# CTRL_MMR0_CFG0 register map
Vendor: Texas Instruments
Registers are 32-bit, read-write, reset 0x0 unless marked. A register's access mark holds for its fields unless they carry their own. Offsets are as the file gives them; [hi:lo] are bit positions; {n}, {i} and the like mark numbered series.

## CTRL_MMR0_CFG0 (part 2 of 2)
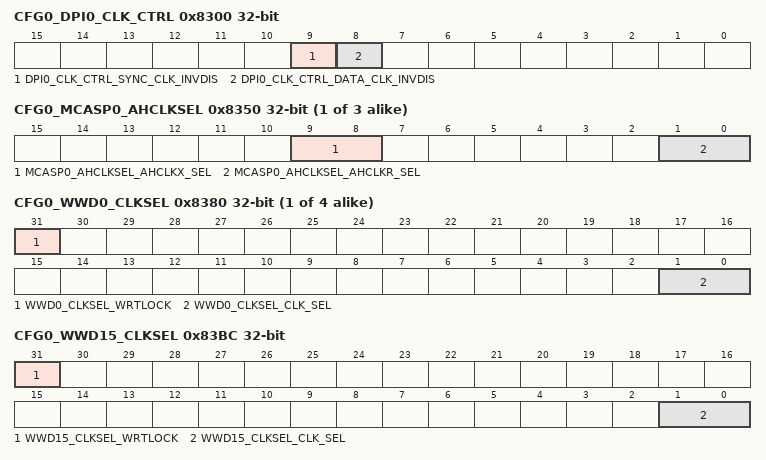
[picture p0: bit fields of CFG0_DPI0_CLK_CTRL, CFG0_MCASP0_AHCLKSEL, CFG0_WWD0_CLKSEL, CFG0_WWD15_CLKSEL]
0x8300 CFG0_DPI0_CLK_CTRL
  [9] DPI0_CLK_CTRL_SYNC_CLK_INVDIS — Clock edge select for DPI0 sync outputs 0 - HSYNC and VSYNC are driven on the falling edge of clk 1 - HSYNC and VSYNC are driven on the rising edge of clk Note that this value should align with the programmed value of the DSS POL_FREQ.RF bitfield.8
  [8] DPI0_CLK_CTRL_DATA_CLK_INVDIS — Clock edge select for DPI0 data outputs 0 - DATA and DE are driven on the falling edge of clk 1 - DATA and DE are driven on the rising edge of clk Note that this value should align with the programmed valueof the DSS POL_FREQ.IPC bitfield.0
0x8320 CFG0_DSS_DISPC0_CLKSEL1
  [0] DSS_DISPC0_CLKSEL1_DPI1_PCLK — DPI Lane 1 pixel Clock Source Field values (others are reserved): 1'b0 - MAIN_PLL17_HSDIV0_CLKOUT 1'b1 - VOUT0_EXTPCLKIN
{0x8330+4i} CFG0_MCASP{i}_CLKSEL (i=0..2)
  [0] MCASP{i}_CLKSEL_AUXCLK_SEL — Selects the AUXCLK input source for McASP0 Field values (others are reserved): 1'b0 - MAIN_PLL2_HSDIV8_CLKOUT 1'b1 - MAIN_PLL1_HSDIV6_CLKOUT
{0x8350+4i} CFG0_MCASP{i}_AHCLKSEL (i=0..2)
  [9:8] MCASP{i}_AHCLKSEL_AHCLKX_SEL — Selects the AHCLKX input source for McASP{i} Field values (others are reserved): 2'b00 - EXT_REFCLK1 (pin) 2'b01 - HFOSC0_CLKOUT 2'b10 - AUDIO_EXT_REFCLK0_IN 2'b11 - AUDIO_EXT_REFCLK1_IN
  [1:0] MCASP{i}_AHCLKSEL_AHCLKR_SEL — Selects the AHCLKR input source for McASP{i} Field values (others are reserved): 2'b00 - EXT_REFCLK1 (pin) 2'b01 - HFOSC0_CLKOUT 2'b10 - AUDIO_EXT_REFCLK0_IN 2'b11 - AUDIO_EXT_REFCLK1_IN
{0x8380+4i} CFG0_WWD{i}_CLKSEL (i=0..3)
  [31] WWD{i}_CLKSEL_WRTLOCK — When set, locks WWD{i}_CLKSEL from further writes until the next module reset.
  [1:0] WWD{i}_CLKSEL_CLK_SEL — Windowed watchdog timer functional clock input select mux control Field values (others are reserved): 2'b00 - HFOSC0_CLKOUT 2'b01 - DEVICE_CLKOUT_32K 2'b10 - CLK_12M_RC 2'b11 - CLK_32K
0x83BC CFG0_WWD15_CLKSEL
  [31] WWD15_CLKSEL_WRTLOCK — When set, locks WWD15_CLKSEL from further writes until the next module reset.
  [1:0] WWD15_CLKSEL_CLK_SEL — Windowed watchdog timer functional clock input select mux control Field values (others are reserved): 2'b00 - HFOSC0_CLKOUT 2'b01 - DEVICE_CLKOUT_32K 2'b10 - CLK_12M_RC 2'b11 - CLK_32K
0x8480 CFG0_MCAN0_CLKSEL
  [1:0] MCAN0_CLKSEL_CLK_SEL — MAIN MCAN_CLK selection 2'b00 - MAIN_PLL0_HSDIV3_CLKOUT 2'b01 - MCU_EXT_REFCLK0 (pin) 2'b10 - EXT_REFCLK0 (pin) 2'b11 - HFOSC0_CLKOUT Field values (others are reserved): 2'b00 - MAIN_PLL0_HSDIV4_CLKOUT 2'b01 - MCU_EXT_REFCLK0 2'b10 - EXT_REFCLK1 (pin) 2'b11 - HFOSC0_CLKOUT
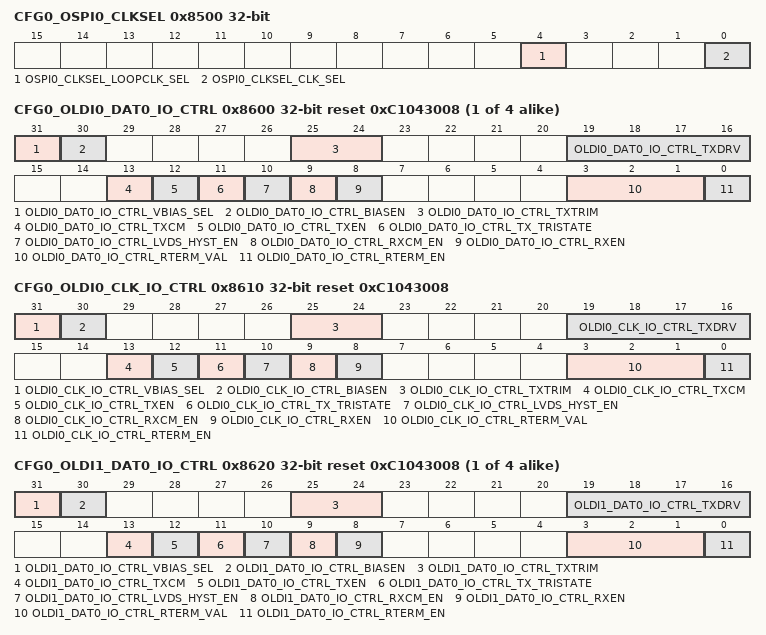
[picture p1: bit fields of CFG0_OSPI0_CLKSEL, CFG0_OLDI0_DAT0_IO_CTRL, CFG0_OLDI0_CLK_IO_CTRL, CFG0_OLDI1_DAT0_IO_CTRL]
0x8500 CFG0_OSPI0_CLKSEL
  [4] OSPI0_CLKSEL_LOOPCLK_SEL — OBSPI0 Loopback clock source Field values (others are reserved): 1'b0 - Board Level Loopback 1'b1 - Internal Loopback
  [0] OSPI0_CLKSEL_CLK_SEL — OSPI0 reference clock selection Field values (others are reserved): 1'b0 - MAIN_PLL0_HSDIV1_CLKOUT 1'b1 - MAIN_PLL1_HSDIV5_CLKOUT
{0x8600+4i} CFG0_OLDI0_DAT{i}_IO_CTRL reset 0xC1043008 (i=0..3)
  [31] OLDI0_DAT{i}_IO_CTRL_VBIAS_SEL — Selects LVDS IO Bias Voltage
  [30] OLDI0_DAT{i}_IO_CTRL_BIASEN — Controls LVDS IO BIAS_EN if OLDI is activated
  [25:24] OLDI0_DAT{i}_IO_CTRL_TXTRIM — Controls LVDS Transmitter TXTRIM
  [19:16] OLDI0_DAT{i}_IO_CTRL_TXDRV — Controls LVDS Transmitter TXDRV
  [13] OLDI0_DAT{i}_IO_CTRL_TXCM — Controls LVDS Transmitter TX_CM
  [12] OLDI0_DAT{i}_IO_CTRL_TXEN — Controls LVDS Transmitter TXEN if BIAS_EN is active
  [11] OLDI0_DAT{i}_IO_CTRL_TX_TRISTATE — Controls LVDS Transmitter TX_TRISTATE input if BIAS_EN is active
  [10] OLDI0_DAT{i}_IO_CTRL_LVDS_HYST_EN — Controls LVDS Receiver Hysteresis
  [9] OLDI0_DAT{i}_IO_CTRL_RXCM_EN — Controls LVDS Receiver RXCM_EN
  [8] OLDI0_DAT{i}_IO_CTRL_RXEN — Controls LVDS Receiver RXEN when BIAS_EN is active
  [3:1] OLDI0_DAT{i}_IO_CTRL_RTERM_VAL — Controls LVDS Receiver RTERM_VAL
  [0] OLDI0_DAT{i}_IO_CTRL_RTERM_EN — Controls LVDS Receiver RTERM_EN
0x8610 CFG0_OLDI0_CLK_IO_CTRL reset 0xC1043008
  [31] OLDI0_CLK_IO_CTRL_VBIAS_SEL — Selects LVDS IO Bias Voltage
  [30] OLDI0_CLK_IO_CTRL_BIASEN — Controls LVDS IO BIAS_EN if OLDI is activated
  [25:24] OLDI0_CLK_IO_CTRL_TXTRIM — Controls LVDS Transmitter TXTRIM
  [19:16] OLDI0_CLK_IO_CTRL_TXDRV — Controls LVDS Transmitter TXDRV
  [13] OLDI0_CLK_IO_CTRL_TXCM — Controls LVDS Transmitter TX_CM
  [12] OLDI0_CLK_IO_CTRL_TXEN — Controls LVDS Transmitter TXEN if BIAS_EN is active
  [11] OLDI0_CLK_IO_CTRL_TX_TRISTATE — Controls LVDS Transmitter TX_TRISTATE input if BIAS_EN is active
  [10] OLDI0_CLK_IO_CTRL_LVDS_HYST_EN — Controls LVDS Receiver Hysteresis
  [9] OLDI0_CLK_IO_CTRL_RXCM_EN — Controls LVDS Receiver RXCM_EN
  [8] OLDI0_CLK_IO_CTRL_RXEN — Controls LVDS Receiver RXEN when BIAS_EN is active
  [3:1] OLDI0_CLK_IO_CTRL_RTERM_VAL — Controls LVDS Receiver RTERM_VAL
  [0] OLDI0_CLK_IO_CTRL_RTERM_EN — Controls LVDS Receiver RTERM_EN
{0x8620+4i} CFG0_OLDI1_DAT{i}_IO_CTRL reset 0xC1043008 (i=0..3)
  [31] OLDI1_DAT{i}_IO_CTRL_VBIAS_SEL — Selects LVDS IO Bias Voltage
  [30] OLDI1_DAT{i}_IO_CTRL_BIASEN — Controls LVDS IO BIAS_EN if OLDI is activated
  [25:24] OLDI1_DAT{i}_IO_CTRL_TXTRIM — Controls LVDS Transmitter TXTRIM
  [19:16] OLDI1_DAT{i}_IO_CTRL_TXDRV — Controls LVDS Transmitter TXDRV
  [13] OLDI1_DAT{i}_IO_CTRL_TXCM — Controls LVDS Transmitter TX_CM
  [12] OLDI1_DAT{i}_IO_CTRL_TXEN — Controls LVDS Transmitter TXEN if BIAS_EN is active
  [11] OLDI1_DAT{i}_IO_CTRL_TX_TRISTATE — Controls LVDS Transmitter TX_TRISTATE input if BIAS_EN is active
  [10] OLDI1_DAT{i}_IO_CTRL_LVDS_HYST_EN — Controls LVDS Receiver Hysteresis
  [9] OLDI1_DAT{i}_IO_CTRL_RXCM_EN — Controls LVDS Receiver RXCM_EN
  [8] OLDI1_DAT{i}_IO_CTRL_RXEN — Controls LVDS Receiver RXEN when BIAS_EN is active
  [3:1] OLDI1_DAT{i}_IO_CTRL_RTERM_VAL — Controls LVDS Receiver RTERM_VAL
  [0] OLDI1_DAT{i}_IO_CTRL_RTERM_EN — Controls LVDS Receiver RTERM_EN
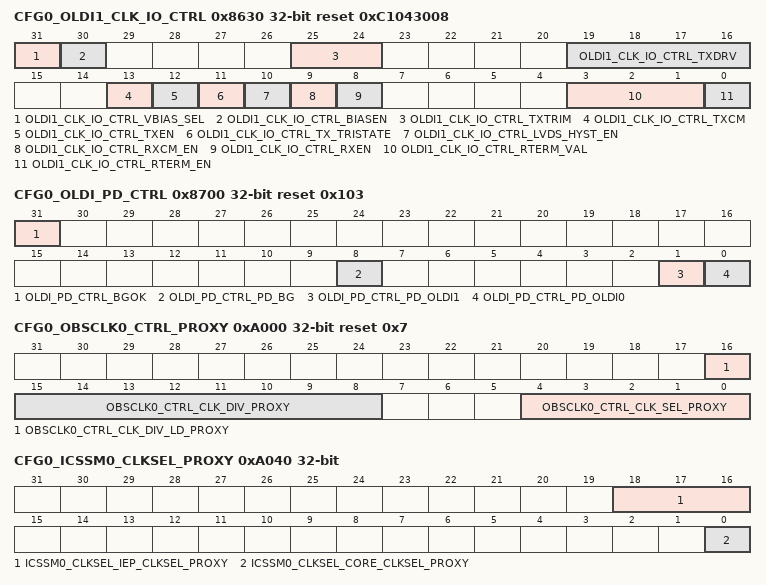
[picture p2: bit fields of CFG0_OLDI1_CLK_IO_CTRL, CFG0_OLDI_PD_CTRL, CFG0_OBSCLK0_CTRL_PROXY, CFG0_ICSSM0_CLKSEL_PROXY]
0x8630 CFG0_OLDI1_CLK_IO_CTRL reset 0xC1043008
  [31] OLDI1_CLK_IO_CTRL_VBIAS_SEL — Selects LVDS IO Bias Voltage
  [30] OLDI1_CLK_IO_CTRL_BIASEN — Controls LVDS IO BIAS_EN if OLDI is activated
  [25:24] OLDI1_CLK_IO_CTRL_TXTRIM — Controls LVDS Transmitter TXTRIM
  [19:16] OLDI1_CLK_IO_CTRL_TXDRV — Controls LVDS Transmitter TXDRV
  [13] OLDI1_CLK_IO_CTRL_TXCM — Controls LVDS Transmitter TX_CM
  [12] OLDI1_CLK_IO_CTRL_TXEN — Controls LVDS Transmitter TXEN if BIAS_EN is active
  [11] OLDI1_CLK_IO_CTRL_TX_TRISTATE — Controls LVDS Transmitter TX_TRISTATE input if BIAS_EN is active
  [10] OLDI1_CLK_IO_CTRL_LVDS_HYST_EN — Controls LVDS Receiver Hysteresis
  [9] OLDI1_CLK_IO_CTRL_RXCM_EN — Controls LVDS Receiver RXCM_EN
  [8] OLDI1_CLK_IO_CTRL_RXEN — Controls LVDS Receiver RXEN when BIAS_EN is active
  [3:1] OLDI1_CLK_IO_CTRL_RTERM_VAL — Controls LVDS Receiver RTERM_VAL
  [0] OLDI1_CLK_IO_CTRL_RTERM_EN — Controls LVDS Receiver RTERM_EN
0x8700 CFG0_OLDI_PD_CTRL access per field reset 0x103
  [31] OLDI_PD_CTRL_BGOK ro — Status of the Bandgap: 1 = Bandgap is On
  [8] OLDI_PD_CTRL_PD_BG rw — When Set, forces the LVDS Bandgap into Power Down
  [1] OLDI_PD_CTRL_PD_OLDI1 rw — When Set, overrides the biase_en of all OLDI1 LVDS IO to force power down
  [0] OLDI_PD_CTRL_PD_OLDI0 rw — When Set, overrides the biase_en of all OLDI0 LVDS IO to force power down
0x8704 CFG0_OLDI_LB_CTRL
  [0] OLDI_LB_CTRL_OLDI_SEL — When: 0 - OLDI0 loopback data is routed to DSS 1 - OLDI1 loopback data is routed to DSS
{0x9100+4i} CFG0_CLAIMREG_P2_R{i}_READONLY ro (i=0..14)
  [31:0] CLAIMREG_P2_R{i}_READONLY — Claim bits for Partition 2
0xA000 CFG0_OBSCLK0_CTRL_PROXY reset 0x7
  [16] OBSCLK0_CTRL_CLK_DIV_LD_PROXY — Load the output divider value Writing 1 to this bit will generate a load pulse to load the OBSCLK0 divider value. This bit can be cleared but must not be set in the same write cycle in which the clk_div value is changed.
  [15:8] OBSCLK0_CTRL_CLK_DIV_PROXY — OBSCLK0 output divider Divides the selected clock by clkdiv+1 for output to the OBSCLK0 pins. Supports divide by 1 to 256 (default to 1). To load the new divider value the clk_div_ld bit must be cleared and then set to 1.
  [4:0] OBSCLK0_CTRL_CLK_SEL_PROXY — OBSCLK0 clock source selection. Selects the source of the clock to be divided by the OBSCLK0 divider and output on the OBSCLK0 pin. Field values (others are reserved): 5'b00000 - MAIN_PLL0_HSDIV0_CLKOUT 5'b00001 - MAIN_PLL1_HSDIV0_CLKOUT 5'b00010 - MAIN_PLL2_HSDIV0_CLKOUT 5'b00011 - MAIN_PLL8_HSDIV0_CLKOUT 5'b00100 - MAIN_PLL12_HSDIV0_CLKOUT 5'b00101 - CLK_12M_RC 5'b00110 - HFOSC0_CLKOUT_32K 5'b00111 - PLLCTRL_OBSCLK 5'b01000 - HFOSC0_CLKOUT 5'b01001 - CLK_32K 5'b01010 - cpsw2g_cpts_genf0 5'b01011 - cpsw2g_cpts_genf1 5'b01100 - MCU_PLL0_HSDIV0_CLKOUT 5'b01101 - MAIN_PLL15_HSDIV0_CLKOUT 5'b01110 - MAIN_PLL16_HSDIV0_CLKOUT 5'b01111 - MAIN_PLL17_HSDIV0_CLKOUT 5'b10000 - MAIN_SYSCLK0 5'b10001 - DEVICE_CLKOUT_32K
0xA010 CFG0_CLKOUT_CTRL_PROXY
  [0] CLKOUT_CTRL_CLK_SEL_PROXY — Selects CLKOUT clock source Field values (others are reserved): 1'b0 - MAIN_PLL2_HSDIV1_CLKOUT / 5 1'b1 - MAIN_PLL2_HSDIV1_CLKOUT / 10
0xA040 CFG0_ICSSM0_CLKSEL_PROXY
  [18:16] ICSSM0_CLKSEL_IEP_CLKSEL_PROXY — Selects the ICSSM0 IEP clock source Field values (others are reserved): 3'b000 - MAIN_PLL2_HSDIV5_CLKOUT 3'b001 - MAIN_PLL0_HSDIV6_CLKOUT 3'b010 - CPGEMAC_CPTS_RFT_CLK 3'b011 - reserved 3'b100 - MCU_EXT_REFCLK0 3'b101 - EXT_REFCLK1 3'b110 - MCU_SYSCLK0 3'b111 - MAIN_SYSCLK0
  [0] ICSSM0_CLKSEL_CORE_CLKSEL_PROXY — Selects the ICSSM0 functional clock source Field values (others are reserved): 1'b0 - MAIN_PLL2_HSDIV0_CLKOUT 1'b1 - MAIN_PLL0_HSDIV9_CLKOUT
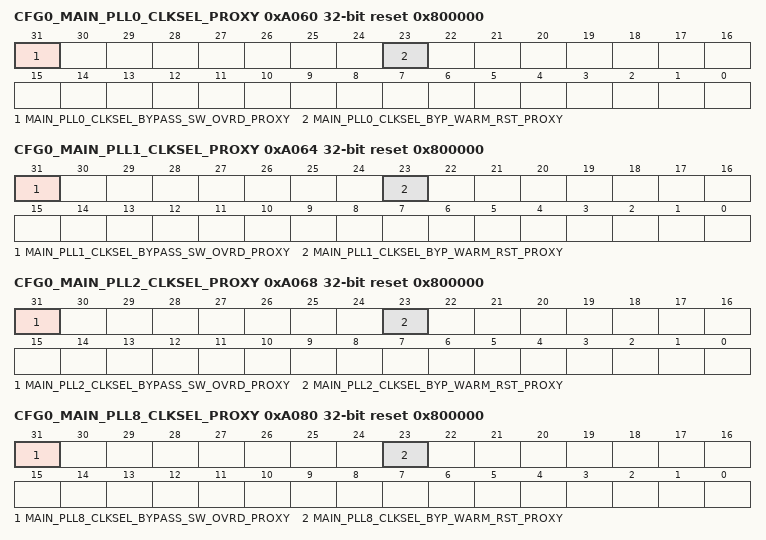
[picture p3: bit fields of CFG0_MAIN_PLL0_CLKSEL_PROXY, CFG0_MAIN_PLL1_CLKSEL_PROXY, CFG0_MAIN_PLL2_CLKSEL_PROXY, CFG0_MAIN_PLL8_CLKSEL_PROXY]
0xA060 CFG0_MAIN_PLL0_CLKSEL_PROXY reset 0x800000
  [31] MAIN_PLL0_CLKSEL_BYPASS_SW_OVRD_PROXY — PLL Bypass warm reset software override When set, activates software control of exit from bypass mode on a main_reset_z for MAIN PLL0. This bit must not be set until after the corresponding byp_warm_rst bit has been cleared or the PLL will immediately enter bypass mode.
  [23] MAIN_PLL0_CLKSEL_BYP_WARM_RST_PROXY — PLL bypass mode after warm reset. This bit is only valid when bypass_sw_ovrd is set to 1'b1 to activate bypass software override. This bit is set (1'b0) when a MAIN warm reset occurs to keep MAIN PLL0 from being bypassed, supporting reset isolation of the CPSW. 1'b0 = Exit bypass mode (based on MAIN PLL0_CTRL_bypass_en bit value) 1'b1 = Maintain bypass mode.
0xA064 CFG0_MAIN_PLL1_CLKSEL_PROXY reset 0x800000
  [31] MAIN_PLL1_CLKSEL_BYPASS_SW_OVRD_PROXY — PLL Bypass warm reset software override This bit has no effect on PLL operation as MAIN PLL1 is reset isolated and exit from bypass mode (in the case of a Thermal reset) is always hardware controlled.
  [23] MAIN_PLL1_CLKSEL_BYP_WARM_RST_PROXY — PLL bypass mode after warm reset. This bit is cleared to 1'b0 when a MAIN warm reset occurs which will cause MAIN PLL1 to exit bypass mode after reset exit. Setting this bit will have no effect on PLL behaviot. Because MAIN PLL1 is warm reset insensitive, bypass mode will only be entered (and exited) in the case of a Thermal reset event.
0xA068 CFG0_MAIN_PLL2_CLKSEL_PROXY reset 0x800000
  [31] MAIN_PLL2_CLKSEL_BYPASS_SW_OVRD_PROXY — PLL Bypass warm reset software override This bit has no effect on PLL operation as MAIN PLL2 is reset isolated and exit from bypass mode (in the case of a Thermal reset) is always hardware controlled.
  [23] MAIN_PLL2_CLKSEL_BYP_WARM_RST_PROXY — PLL bypass mode after warm reset. This bit is cleared to 1'b0 when a MAIN warm reset occurs which will cause MAIN PLL2 to exit bypass mode after reset exit. Setting this bit will have no effect on PLL behaviot. Because MAIN PLL2 is warm reset insensitive, bypass mode will only be entered (and exited) in the case of a Thermal reset event.
0xA080 CFG0_MAIN_PLL8_CLKSEL_PROXY reset 0x800000
  [31] MAIN_PLL8_CLKSEL_BYPASS_SW_OVRD_PROXY — PLL Bypass warm reset software override When set, activates software control of exit from bypass mode on a main_reset_z for MAIN PLL8. This bit must not be set until after the corresponding byp_warm_rst bit has been cleared or the PLL will immediately enter bypass mode.
  [23] MAIN_PLL8_CLKSEL_BYP_WARM_RST_PROXY — PLL bypass mode after warm reset. This bit is only valid when bypass_sw_ovrd is set to 1'b1 to activate bypass software override. This bit is set (1'b1) when a MAIN warm reset occurs and will keep MAIN PLL8 in bypass mode after reset exit until cleared by software. 1'b0 = Exit bypass mode (based on MAIN PLL8_CTRL_bypass_en bit value) 1'b1 = Maintain bypass mode.
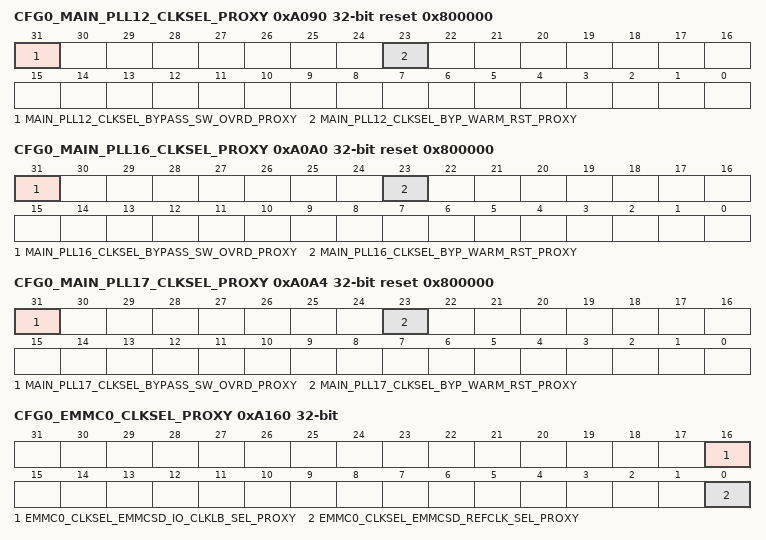
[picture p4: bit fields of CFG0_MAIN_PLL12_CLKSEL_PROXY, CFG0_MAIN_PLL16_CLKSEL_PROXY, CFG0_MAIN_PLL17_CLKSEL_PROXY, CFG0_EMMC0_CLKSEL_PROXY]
0xA090 CFG0_MAIN_PLL12_CLKSEL_PROXY reset 0x800000
  [31] MAIN_PLL12_CLKSEL_BYPASS_SW_OVRD_PROXY — PLL Bypass warm reset software override When set, activates software control of exit from bypass mode on a main_reset_z for MAIN PLL12. This bit must not be set until after the corresponding byp_warm_rst bit has been cleared or the PLL will immediately enter bypass mode.
  [23] MAIN_PLL12_CLKSEL_BYP_WARM_RST_PROXY — PLL bypass mode after warm reset. This bit is only valid when bypass_sw_ovrd is set to 1'b1 to activate bypass software override. This bit is set (1'b1) when a MAIN warm reset occurs and will keep MAIN PLL12 in bypass mode after reset exit until cleared by software. 1'b0 = Exit bypass mode (based on MAIN PLL12_CTRL_bypass_en bit value) 1'b1 = Maintain bypass mode.
0xA0A0 CFG0_MAIN_PLL16_CLKSEL_PROXY reset 0x800000
  [31] MAIN_PLL16_CLKSEL_BYPASS_SW_OVRD_PROXY — PLL Bypass warm reset software override This bit has no effect on PLL operation as MAIN PLL16 is reset isolated and exit from bypass mode (in the case of a Thermal reset) is always hardware controlled.
  [23] MAIN_PLL16_CLKSEL_BYP_WARM_RST_PROXY — PLL bypass mode after warm reset. This bit is cleared to 1'b0 when a MAIN warm reset occurs which will cause MAIN PLL16 to exit bypass mode after reset exit. Setting this bit will have no effect on PLL behaviot. Because MAIN PLL16 is warm reset insensitive, bypass mode will only be entered (and exited) in the case of a Thermal reset event.
0xA0A4 CFG0_MAIN_PLL17_CLKSEL_PROXY reset 0x800000
  [31] MAIN_PLL17_CLKSEL_BYPASS_SW_OVRD_PROXY — PLL Bypass warm reset software override This bit has no effect on PLL operation as MAIN PLL17 is reset isolated and exit from bypass mode (in the case of a Thermal reset) is always hardware controlled.
  [23] MAIN_PLL17_CLKSEL_BYP_WARM_RST_PROXY — PLL bypass mode after warm reset. This bit is cleared to 1'b0 when a MAIN warm reset occurs which will cause MAIN PLL17 to exit bypass mode after reset exit. Setting this bit will have no effect on PLL behaviot. Because MAIN PLL17 is warm reset insensitive, bypass mode will only be entered (and exited) in the case of a Thermal reset event.
0xA140 CFG0_CPSW_CLKSEL_PROXY reset 0x7
  [2:0] CPSW_CLKSEL_CPTS_CLKSEL_PROXY — Selects the clock source for the CPSW Ethernet switch Common Platform Time Stamp module Field values (others are reserved): 3'b000 - MAIN_PLL2_HSDIV5_CLKOUT 3'b001 - MAIN_PLL0_HSDIV6_CLKOUT 3'b010 - CP_GEMAC_CPTS0_RFT_CLK (Pin) 3'b011 - Reserved 3'b100 - MCU_EXT_REFCLK0 (Pin) 3'b101 - EXT_REFCLK1 (Pin) 3'b110 - MCU_SYSCLK0 3'b111 - MAIN_SYSCLK0
0xA160 CFG0_EMMC0_CLKSEL_PROXY
  [16] EMMC0_CLKSEL_EMMCSD_IO_CLKLB_SEL_PROXY — Selects IO Pad Loopback for the MMC Module Field values (others are reserved): 1'b0 - Loopback from Unbonded Pad MMCSD0_CLKLB 1'b1 - Loopback from IO Pin MMCSD0_CLK
  [0] EMMC0_CLKSEL_EMMCSD_REFCLK_SEL_PROXY — Selects the functional clock for the MMC Module Field values (others are reserved): 1'b0 - MAIN_PLL0_HSDIV5_CLKOUT 1'b1 - MAIN_PLL2_HSDIV2_CLKOUT
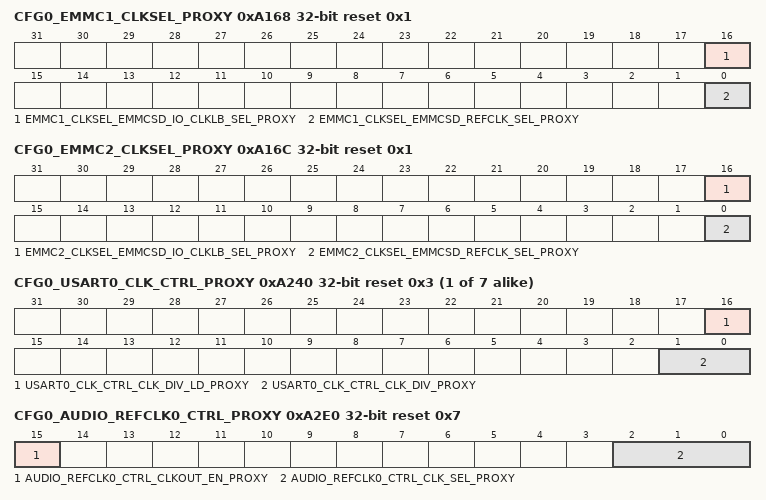
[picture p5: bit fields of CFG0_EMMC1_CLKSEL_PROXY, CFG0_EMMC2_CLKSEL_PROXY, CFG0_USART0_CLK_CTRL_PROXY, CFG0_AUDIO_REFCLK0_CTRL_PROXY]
0xA168 CFG0_EMMC1_CLKSEL_PROXY reset 0x1
  [16] EMMC1_CLKSEL_EMMCSD_IO_CLKLB_SEL_PROXY — Selects IO Pad Loopback for the MMC Module Field values (others are reserved): 1'b0 - Loopback from Unbonded Pad MMCSD1_CLKLB 1'b1 - Loopback from IO Pin MMCSD1_CLK
  [0] EMMC1_CLKSEL_EMMCSD_REFCLK_SEL_PROXY — Selects the functional clock for the MMC Module Field values (others are reserved): 1'b0 - MAIN_PLL0_HSDIV5_CLKOUT 1'b1 - MAIN_PLL2_HSDIV2_CLKOUT
0xA16C CFG0_EMMC2_CLKSEL_PROXY reset 0x1
  [16] EMMC2_CLKSEL_EMMCSD_IO_CLKLB_SEL_PROXY — Selects IO Pad Loopback for the MMC Module Field values (others are reserved): 1'b0 - Loopback from Unbonded Pad MMCSD2_CLKLB 1'b1 - Loopback from IO Pin MMCSD2_CLK
  [0] EMMC2_CLKSEL_EMMCSD_REFCLK_SEL_PROXY — Selects the functional clock for the MMC Module Field values (others are reserved): 1'b0 - MAIN_PLL0_HSDIV5_CLKOUT 1'b1 - MAIN_PLL2_HSDIV2_CLKOUT
0xA180 CFG0_GPMC_CLKSEL_PROXY
  [0] GPMC_CLKSEL_CLK_SEL_PROXY — Selects the GPMC clock source: Field values (others are reserved): 1'b0 - MAIN_PLL0_HSDIV3_CLKOUT 1'b1 - MAIN_PLL2_HSDIV7_CLKOUT
{0xA1B0+4i} CFG0_TIMER{i}_CLKSEL_PROXY (i=0..7)
  [3:0] TIMER{i}_CLKSEL_CLK_SEL_PROXY — Timer functional clock input select mux control (Reserved values default to HFOSC1_CLK) Field values (others are reserved): 4'b0000 - HFOSC0_CLKOUT 4'b0001 - FINAL_CLKOUT_32K 4'b0010 - MAIN_PLL0_HSDIV7_CLKOUT 4'b0011 - CLK_12M_RC 4'b0100 - MCU_EXT_REFCLK0 (pin) 4'b0101 - EXT_REFCLK1 (pin) 4'b0110 - Reserved 4'b0111 - CPSW2G_CPTS_RFT_CLK 4'b1000 - MAIN_PLL1_HSDIV3_CLKOUT 4'b1001 - MAIN_PLL2_HSDIV6_CLKOUT 4'b1010 - CPSW2G_CPTS_GENF0 4'b1011 - CPSW2G_CPTS_GENF1 4'b1100 - Reserved 4'b1101 - Reserved 4'b1110 - Reserved 4'b1111 - Reserved
{0xA200+4i} CFG0_SPI{i}_CLKSEL_PROXY (i=0..2)
  [16] SPI{i}_CLKSEL_MSTR_LB_CLKSEL_PROXY — Controller mode receive capture clock loopback selection 1'b0 - Internal clock loopback 1'b1 - Loopback from pad
{0xA240+4i} CFG0_USART{i}_CLK_CTRL_PROXY reset 0x3 (i=0..6)
  [16] USART{i}_CLK_CTRL_CLK_DIV_LD_PROXY — Load the output divider value Writing 1 to this bit will generate a load pulse to load the USART{i} clock programmable divider value. This bit can be cleared but must not be set in the same write cycle in which the clk_div value is changed.
  [1:0] USART{i}_CLK_CTRL_CLK_DIV_PROXY — Selects the clock divider value. Supports divide values of 1 to 4 Default is /4. To load the new divider value the clk_div_ld bit must be cleared and then set to 1. Field values (others are reserved): 2'b00 - Divide by 1 2'b01 - Divide by 2 2'b10 - Divide by 3 2'b11 - Divide by 4
{0xA280+4i} CFG0_USART{i}_CLKSEL_PROXY (i=0..6)
  [0] USART{i}_CLKSEL_CLK_SEL_PROXY — Selects the clock source for UART{i}: Field values (others are reserved): 1'b0 - MAIN_PLL1_HSDIV0_CLKOUT Divider Output (See USART{i}_CLK_CTRL) 1'b1 - MAIN_PLL1_HSDIV1_CLKOUT
0xA2E0 CFG0_AUDIO_REFCLK0_CTRL_PROXY reset 0x7
  [15] AUDIO_REFCLK0_CTRL_CLKOUT_EN_PROXY — AUDIO_REFCLK 0 output activate This bit is inverted to drive the active low output buffer activate 0 - AUDIO_EXT_REFCLK0 pin is configured as an input 1 - AUDIO_EXT_REFCLK0 pin is configured as an output
  [2:0] AUDIO_REFCLK0_CTRL_CLK_SEL_PROXY — Selects the source of AUDIO_REFCLK0 Field values (others are reserved): 3'b000 - MCASP0_AHCLKR 3'b001 - MCASP1_AHCLKR 3'b010 - MCASP2_AHCLKR 3'b011 - MCASP0_AHCLKX 3'b100 - MCASP1_AHCLKX 3'b101 - MCASP2_AHCLKX 3'b110 - MAIN_PLL1_HSDIV6_CLKOUT 3'b111 - MAIN_PLL1_HSDIV8_CLKOUT
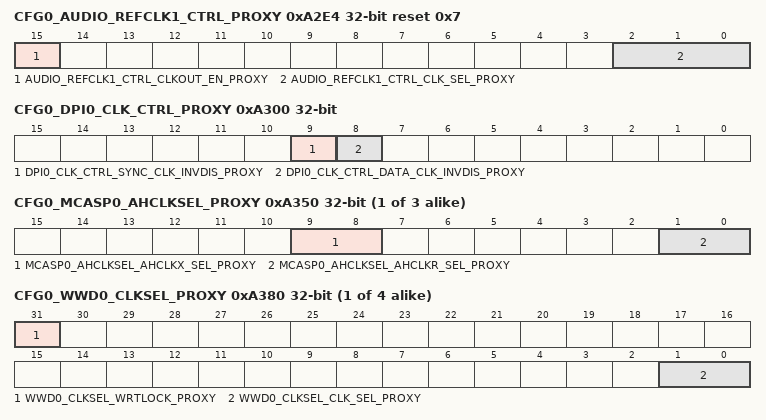
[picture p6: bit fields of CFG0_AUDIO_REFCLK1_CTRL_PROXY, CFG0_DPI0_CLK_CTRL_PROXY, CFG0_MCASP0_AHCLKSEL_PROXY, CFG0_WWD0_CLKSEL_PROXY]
0xA2E4 CFG0_AUDIO_REFCLK1_CTRL_PROXY reset 0x7
  [15] AUDIO_REFCLK1_CTRL_CLKOUT_EN_PROXY — AUDIO_REFCLK 1 output activate This bit is inverted to drive the active low output buffer activate 0 - AUDIO_EXT_REFCLK1 pin is configured as an input 1 - AUDIO_EXT_REFCLK1 pin is configured as an output
  [2:0] AUDIO_REFCLK1_CTRL_CLK_SEL_PROXY — Selects the source of AUDIO_REFCLK1 Field values (others are reserved): 3'b000 - MCASP0_AHCLKR 3'b001 - MCASP1_AHCLKR 3'b010 - MCASP2_AHCLKR 3'b011 - MCASP0_AHCLKX 3'b100 - MCASP1_AHCLKX 3'b101 - MCASP2_AHCLKX 3'b110 - MAIN_PLL1_HSDIV6_CLKOUT 3'b111 - MAIN_PLL1_HSDIV8_CLKOUT
0xA300 CFG0_DPI0_CLK_CTRL_PROXY
  [9] DPI0_CLK_CTRL_SYNC_CLK_INVDIS_PROXY — Clock edge select for DPI0 sync outputs 0 - HSYNC and VSYNC are driven on the falling edge of clk 1 - HSYNC and VSYNC are driven on the rising edge of clk Note that this value should align with the programmed value of the DSS POL_FREQ.RF bitfield.8
  [8] DPI0_CLK_CTRL_DATA_CLK_INVDIS_PROXY — Clock edge select for DPI0 data outputs 0 - DATA and DE are driven on the falling edge of clk 1 - DATA and DE are driven on the rising edge of clk Note that this value should align with the programmed valueof the DSS POL_FREQ.IPC bitfield.0
0xA320 CFG0_DSS_DISPC0_CLKSEL1_PROXY
  [0] DSS_DISPC0_CLKSEL1_DPI1_PCLK_PROXY — DPI Lane 1 pixel Clock Source Field values (others are reserved): 1'b0 - MAIN_PLL17_HSDIV0_CLKOUT 1'b1 - VOUT0_EXTPCLKIN
{0xA330+4i} CFG0_MCASP{i}_CLKSEL_PROXY (i=0..2)
  [0] MCASP{i}_CLKSEL_AUXCLK_SEL_PROXY — Selects the AUXCLK input source for McASP0 Field values (others are reserved): 1'b0 - MAIN_PLL2_HSDIV8_CLKOUT 1'b1 - MAIN_PLL1_HSDIV6_CLKOUT
{0xA350+4i} CFG0_MCASP{i}_AHCLKSEL_PROXY (i=0..2)
  [9:8] MCASP{i}_AHCLKSEL_AHCLKX_SEL_PROXY — Selects the AHCLKX input source for McASP{i} Field values (others are reserved): 2'b00 - EXT_REFCLK1 (pin) 2'b01 - HFOSC0_CLKOUT 2'b10 - AUDIO_EXT_REFCLK0_IN 2'b11 - AUDIO_EXT_REFCLK1_IN
  [1:0] MCASP{i}_AHCLKSEL_AHCLKR_SEL_PROXY — Selects the AHCLKR input source for McASP{i} Field values (others are reserved): 2'b00 - EXT_REFCLK1 (pin) 2'b01 - HFOSC0_CLKOUT 2'b10 - AUDIO_EXT_REFCLK0_IN 2'b11 - AUDIO_EXT_REFCLK1_IN
{0xA380+4i} CFG0_WWD{i}_CLKSEL_PROXY (i=0..3)
  [31] WWD{i}_CLKSEL_WRTLOCK_PROXY — When set, locks WWD{i}_CLKSEL from further writes until the next module reset.
  [1:0] WWD{i}_CLKSEL_CLK_SEL_PROXY — Windowed watchdog timer functional clock input select mux control Field values (others are reserved): 2'b00 - HFOSC0_CLKOUT 2'b01 - DEVICE_CLKOUT_32K 2'b10 - CLK_12M_RC 2'b11 - CLK_32K
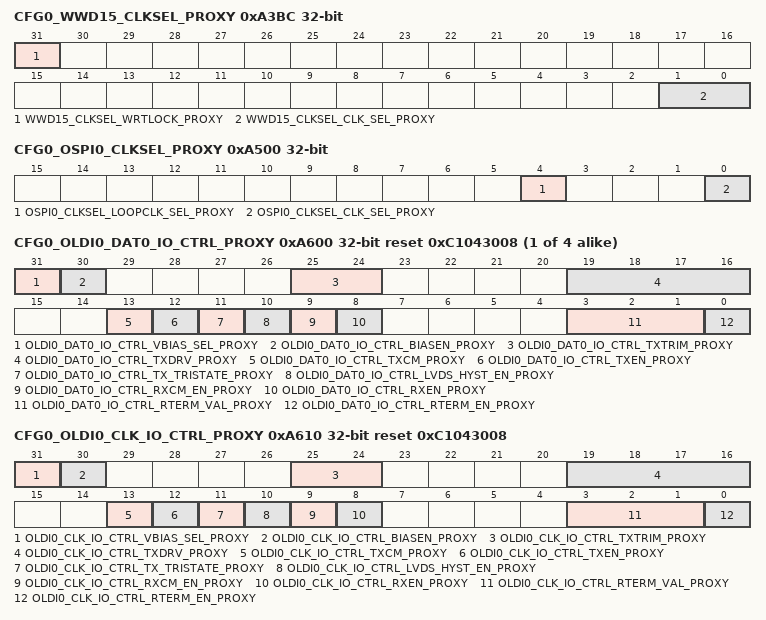
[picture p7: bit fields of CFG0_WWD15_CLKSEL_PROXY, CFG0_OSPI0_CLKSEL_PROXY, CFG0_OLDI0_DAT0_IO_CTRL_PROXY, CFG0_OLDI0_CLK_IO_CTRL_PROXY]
0xA3BC CFG0_WWD15_CLKSEL_PROXY
  [31] WWD15_CLKSEL_WRTLOCK_PROXY — When set, locks WWD15_CLKSEL from further writes until the next module reset.
  [1:0] WWD15_CLKSEL_CLK_SEL_PROXY — Windowed watchdog timer functional clock input select mux control Field values (others are reserved): 2'b00 - HFOSC0_CLKOUT 2'b01 - DEVICE_CLKOUT_32K 2'b10 - CLK_12M_RC 2'b11 - CLK_32K
0xA480 CFG0_MCAN0_CLKSEL_PROXY
  [1:0] MCAN0_CLKSEL_CLK_SEL_PROXY — MAIN MCAN_CLK selection 2'b00 - MAIN_PLL0_HSDIV3_CLKOUT 2'b01 - MCU_EXT_REFCLK0 (pin) 2'b10 - EXT_REFCLK0 (pin) 2'b11 - HFOSC0_CLKOUT Field values (others are reserved): 2'b00 - MAIN_PLL0_HSDIV4_CLKOUT 2'b01 - MCU_EXT_REFCLK0 2'b10 - EXT_REFCLK1 (pin) 2'b11 - HFOSC0_CLKOUT
0xA500 CFG0_OSPI0_CLKSEL_PROXY
  [4] OSPI0_CLKSEL_LOOPCLK_SEL_PROXY — OBSPI0 Loopback clock source Field values (others are reserved): 1'b0 - Board Level Loopback 1'b1 - Internal Loopback
  [0] OSPI0_CLKSEL_CLK_SEL_PROXY — OSPI0 reference clock selection Field values (others are reserved): 1'b0 - MAIN_PLL0_HSDIV1_CLKOUT 1'b1 - MAIN_PLL1_HSDIV5_CLKOUT
{0xA600+4i} CFG0_OLDI0_DAT{i}_IO_CTRL_PROXY reset 0xC1043008 (i=0..3)
  [31] OLDI0_DAT{i}_IO_CTRL_VBIAS_SEL_PROXY — Selects LVDS IO Bias Voltage
  [30] OLDI0_DAT{i}_IO_CTRL_BIASEN_PROXY — Controls LVDS IO BIAS_EN if OLDI is activated
  [25:24] OLDI0_DAT{i}_IO_CTRL_TXTRIM_PROXY — Controls LVDS Transmitter TXTRIM
  [19:16] OLDI0_DAT{i}_IO_CTRL_TXDRV_PROXY — Controls LVDS Transmitter TXDRV
  [13] OLDI0_DAT{i}_IO_CTRL_TXCM_PROXY — Controls LVDS Transmitter TX_CM
  [12] OLDI0_DAT{i}_IO_CTRL_TXEN_PROXY — Controls LVDS Transmitter TXEN if BIAS_EN is active
  [11] OLDI0_DAT{i}_IO_CTRL_TX_TRISTATE_PROXY — Controls LVDS Transmitter TX_TRISTATE input if BIAS_EN is active
  [10] OLDI0_DAT{i}_IO_CTRL_LVDS_HYST_EN_PROXY — Controls LVDS Receiver Hysteresis
  [9] OLDI0_DAT{i}_IO_CTRL_RXCM_EN_PROXY — Controls LVDS Receiver RXCM_EN
  [8] OLDI0_DAT{i}_IO_CTRL_RXEN_PROXY — Controls LVDS Receiver RXEN when BIAS_EN is active
  [3:1] OLDI0_DAT{i}_IO_CTRL_RTERM_VAL_PROXY — Controls LVDS Receiver RTERM_VAL
  [0] OLDI0_DAT{i}_IO_CTRL_RTERM_EN_PROXY — Controls LVDS Receiver RTERM_EN
0xA610 CFG0_OLDI0_CLK_IO_CTRL_PROXY reset 0xC1043008
  [31] OLDI0_CLK_IO_CTRL_VBIAS_SEL_PROXY — Selects LVDS IO Bias Voltage
  [30] OLDI0_CLK_IO_CTRL_BIASEN_PROXY — Controls LVDS IO BIAS_EN if OLDI is activated
  [25:24] OLDI0_CLK_IO_CTRL_TXTRIM_PROXY — Controls LVDS Transmitter TXTRIM
  [19:16] OLDI0_CLK_IO_CTRL_TXDRV_PROXY — Controls LVDS Transmitter TXDRV
  [13] OLDI0_CLK_IO_CTRL_TXCM_PROXY — Controls LVDS Transmitter TX_CM
  [12] OLDI0_CLK_IO_CTRL_TXEN_PROXY — Controls LVDS Transmitter TXEN if BIAS_EN is active
  [11] OLDI0_CLK_IO_CTRL_TX_TRISTATE_PROXY — Controls LVDS Transmitter TX_TRISTATE input if BIAS_EN is active
  [10] OLDI0_CLK_IO_CTRL_LVDS_HYST_EN_PROXY — Controls LVDS Receiver Hysteresis
  [9] OLDI0_CLK_IO_CTRL_RXCM_EN_PROXY — Controls LVDS Receiver RXCM_EN
  [8] OLDI0_CLK_IO_CTRL_RXEN_PROXY — Controls LVDS Receiver RXEN when BIAS_EN is active
  [3:1] OLDI0_CLK_IO_CTRL_RTERM_VAL_PROXY — Controls LVDS Receiver RTERM_VAL
  [0] OLDI0_CLK_IO_CTRL_RTERM_EN_PROXY — Controls LVDS Receiver RTERM_EN
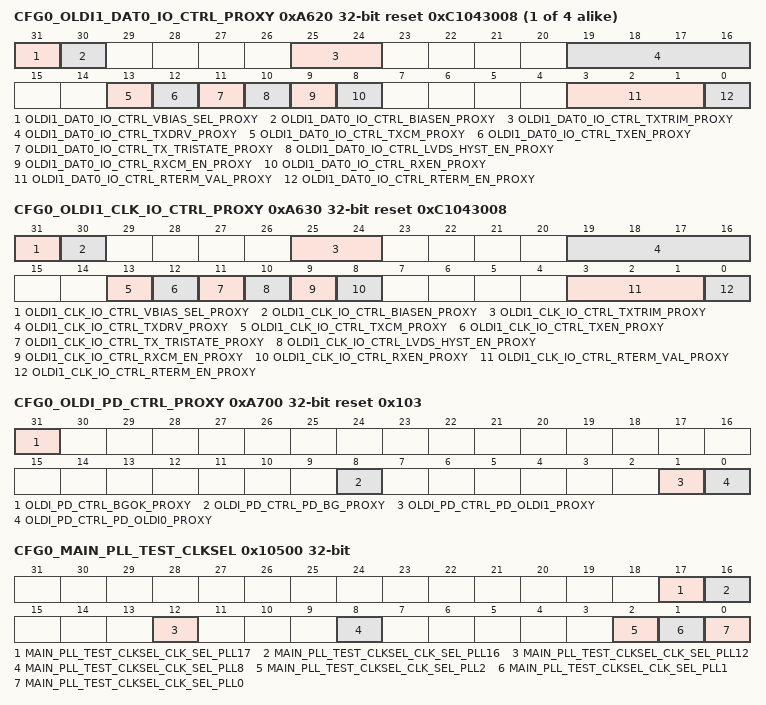
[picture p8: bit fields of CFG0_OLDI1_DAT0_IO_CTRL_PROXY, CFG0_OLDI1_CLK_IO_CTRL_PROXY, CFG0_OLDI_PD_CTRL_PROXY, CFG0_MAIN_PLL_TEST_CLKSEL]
{0xA620+4i} CFG0_OLDI1_DAT{i}_IO_CTRL_PROXY reset 0xC1043008 (i=0..3)
  [31] OLDI1_DAT{i}_IO_CTRL_VBIAS_SEL_PROXY — Selects LVDS IO Bias Voltage
  [30] OLDI1_DAT{i}_IO_CTRL_BIASEN_PROXY — Controls LVDS IO BIAS_EN if OLDI is activated
  [25:24] OLDI1_DAT{i}_IO_CTRL_TXTRIM_PROXY — Controls LVDS Transmitter TXTRIM
  [19:16] OLDI1_DAT{i}_IO_CTRL_TXDRV_PROXY — Controls LVDS Transmitter TXDRV
  [13] OLDI1_DAT{i}_IO_CTRL_TXCM_PROXY — Controls LVDS Transmitter TX_CM
  [12] OLDI1_DAT{i}_IO_CTRL_TXEN_PROXY — Controls LVDS Transmitter TXEN if BIAS_EN is active
  [11] OLDI1_DAT{i}_IO_CTRL_TX_TRISTATE_PROXY — Controls LVDS Transmitter TX_TRISTATE input if BIAS_EN is active
  [10] OLDI1_DAT{i}_IO_CTRL_LVDS_HYST_EN_PROXY — Controls LVDS Receiver Hysteresis
  [9] OLDI1_DAT{i}_IO_CTRL_RXCM_EN_PROXY — Controls LVDS Receiver RXCM_EN
  [8] OLDI1_DAT{i}_IO_CTRL_RXEN_PROXY — Controls LVDS Receiver RXEN when BIAS_EN is active
  [3:1] OLDI1_DAT{i}_IO_CTRL_RTERM_VAL_PROXY — Controls LVDS Receiver RTERM_VAL
  [0] OLDI1_DAT{i}_IO_CTRL_RTERM_EN_PROXY — Controls LVDS Receiver RTERM_EN
0xA630 CFG0_OLDI1_CLK_IO_CTRL_PROXY reset 0xC1043008
  [31] OLDI1_CLK_IO_CTRL_VBIAS_SEL_PROXY — Selects LVDS IO Bias Voltage
  [30] OLDI1_CLK_IO_CTRL_BIASEN_PROXY — Controls LVDS IO BIAS_EN if OLDI is activated
  [25:24] OLDI1_CLK_IO_CTRL_TXTRIM_PROXY — Controls LVDS Transmitter TXTRIM
  [19:16] OLDI1_CLK_IO_CTRL_TXDRV_PROXY — Controls LVDS Transmitter TXDRV
  [13] OLDI1_CLK_IO_CTRL_TXCM_PROXY — Controls LVDS Transmitter TX_CM
  [12] OLDI1_CLK_IO_CTRL_TXEN_PROXY — Controls LVDS Transmitter TXEN if BIAS_EN is active
  [11] OLDI1_CLK_IO_CTRL_TX_TRISTATE_PROXY — Controls LVDS Transmitter TX_TRISTATE input if BIAS_EN is active
  [10] OLDI1_CLK_IO_CTRL_LVDS_HYST_EN_PROXY — Controls LVDS Receiver Hysteresis
  [9] OLDI1_CLK_IO_CTRL_RXCM_EN_PROXY — Controls LVDS Receiver RXCM_EN
  [8] OLDI1_CLK_IO_CTRL_RXEN_PROXY — Controls LVDS Receiver RXEN when BIAS_EN is active
  [3:1] OLDI1_CLK_IO_CTRL_RTERM_VAL_PROXY — Controls LVDS Receiver RTERM_VAL
  [0] OLDI1_CLK_IO_CTRL_RTERM_EN_PROXY — Controls LVDS Receiver RTERM_EN
0xA700 CFG0_OLDI_PD_CTRL_PROXY access per field reset 0x103
  [31] OLDI_PD_CTRL_BGOK_PROXY ro — Status of the Bandgap: 1 = Bandgap is On
  [8] OLDI_PD_CTRL_PD_BG_PROXY rw — When Set, forces the LVDS Bandgap into Power Down
  [1] OLDI_PD_CTRL_PD_OLDI1_PROXY rw — When Set, overrides the biase_en of all OLDI1 LVDS IO to force power down
  [0] OLDI_PD_CTRL_PD_OLDI0_PROXY rw — When Set, overrides the biase_en of all OLDI0 LVDS IO to force power down
0xA704 CFG0_OLDI_LB_CTRL_PROXY
  [0] OLDI_LB_CTRL_OLDI_SEL_PROXY — When: 0 - OLDI0 loopback data is routed to DSS 1 - OLDI1 loopback data is routed to DSS
{0xB100+4i} CFG0_CLAIMREG_P2_R{i} (i=0..14)
  [31:0] CLAIMREG_P2_R{i} — Claim bits for Partition 2
0x10500 CFG0_MAIN_PLL_TEST_CLKSEL
  [17] MAIN_PLL_TEST_CLKSEL_CLK_SEL_PLL17 — Selects the alternate clock source for MAIN PLL17 Field values (others are reserved): 1'b0 - HFOSC0_CLKOUT 1'b1 - EXT_REFCLK1 pin
  [16] MAIN_PLL_TEST_CLKSEL_CLK_SEL_PLL16 — Selects the alternate clock source for MAIN PLL16 Field values (others are reserved): 1'b0 - HFOSC0_CLKOUT 1'b1 - EXT_REFCLK1 pin
  [12] MAIN_PLL_TEST_CLKSEL_CLK_SEL_PLL12 — Selects the alternate clock source for MAIN PLL12 Field values (others are reserved): 1'b0 - HFOSC0_CLKOUT 1'b1 - EXT_REFCLK1 pin
  [8] MAIN_PLL_TEST_CLKSEL_CLK_SEL_PLL8 — Selects the alternate clock source for MAIN PLL8 Field values (others are reserved): 1'b0 - HFOSC0_CLKOUT 1'b1 - EXT_REFCLK1 pin
  [2] MAIN_PLL_TEST_CLKSEL_CLK_SEL_PLL2 — Selects the alternate clock source for MAIN PLL2 Field values (others are reserved): 1'b0 - HFOSC0_CLKOUT 1'b1 - EXT_REFCLK1 pin
  [1] MAIN_PLL_TEST_CLKSEL_CLK_SEL_PLL1 — Selects the alternate clock source for MAIN PLL1 Field values (others are reserved): 1'b0 - HFOSC0_CLKOUT 1'b1 - EXT_REFCLK1 pin
  [0] MAIN_PLL_TEST_CLKSEL_CLK_SEL_PLL0 — Selects the alternate clock source for MAIN PLL0 Field values (others are reserved): 1'b0 - HFOSC0_CLKOUT 1'b1 - EXT_REFCLK1 pin
0x11008 CFG0_LOCK4_KICK0
  [31:0] LOCK4_KICK0 — - KICK0 component
0x1100C CFG0_LOCK4_KICK1
  [31:0] LOCK4_KICK1 — - KICK1 component
{0x11100+4i} CFG0_CLAIMREG_P4_R{i}_READONLY ro (i=0..10)
  [31:0] CLAIMREG_P4_R{i}_READONLY — Claim bits for Partition 4
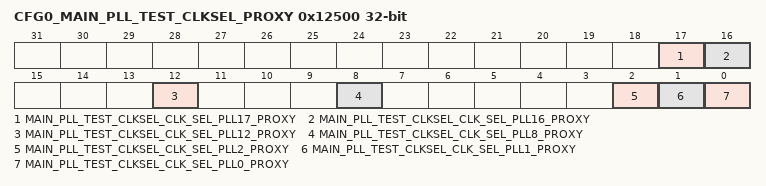
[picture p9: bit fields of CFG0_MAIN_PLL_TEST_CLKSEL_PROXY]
0x12500 CFG0_MAIN_PLL_TEST_CLKSEL_PROXY
  [17] MAIN_PLL_TEST_CLKSEL_CLK_SEL_PLL17_PROXY — Selects the alternate clock source for MAIN PLL17 Field values (others are reserved): 1'b0 - HFOSC0_CLKOUT 1'b1 - EXT_REFCLK1 pin
  [16] MAIN_PLL_TEST_CLKSEL_CLK_SEL_PLL16_PROXY — Selects the alternate clock source for MAIN PLL16 Field values (others are reserved): 1'b0 - HFOSC0_CLKOUT 1'b1 - EXT_REFCLK1 pin
  [12] MAIN_PLL_TEST_CLKSEL_CLK_SEL_PLL12_PROXY — Selects the alternate clock source for MAIN PLL12 Field values (others are reserved): 1'b0 - HFOSC0_CLKOUT 1'b1 - EXT_REFCLK1 pin
  [8] MAIN_PLL_TEST_CLKSEL_CLK_SEL_PLL8_PROXY — Selects the alternate clock source for MAIN PLL8 Field values (others are reserved): 1'b0 - HFOSC0_CLKOUT 1'b1 - EXT_REFCLK1 pin
  [2] MAIN_PLL_TEST_CLKSEL_CLK_SEL_PLL2_PROXY — Selects the alternate clock source for MAIN PLL2 Field values (others are reserved): 1'b0 - HFOSC0_CLKOUT 1'b1 - EXT_REFCLK1 pin
  [1] MAIN_PLL_TEST_CLKSEL_CLK_SEL_PLL1_PROXY — Selects the alternate clock source for MAIN PLL1 Field values (others are reserved): 1'b0 - HFOSC0_CLKOUT 1'b1 - EXT_REFCLK1 pin
  [0] MAIN_PLL_TEST_CLKSEL_CLK_SEL_PLL0_PROXY — Selects the alternate clock source for MAIN PLL0 Field values (others are reserved): 1'b0 - HFOSC0_CLKOUT 1'b1 - EXT_REFCLK1 pin
0x13008 CFG0_LOCK4_KICK0_PROXY
  [31:0] LOCK4_KICK0_PROXY — - KICK0 component
0x1300C CFG0_LOCK4_KICK1_PROXY
  [31:0] LOCK4_KICK1_PROXY — - KICK1 component
{0x13100+4i} CFG0_CLAIMREG_P4_R{i} (i=0..10)
  [31:0] CLAIMREG_P4_R{i} — Claim bits for Partition 4
0x19008 CFG0_LOCK6_KICK0
  [31:0] LOCK6_KICK0 — - KICK0 component
0x1900C CFG0_LOCK6_KICK1
  [31:0] LOCK6_KICK1 — - KICK1 component
{0x19100+4i} CFG0_CLAIMREG_P6_R{i}_READONLY ro (i=0..8)
  [31:0] CLAIMREG_P6_R{i}_READONLY — Claim bits for Partition 6
0x1B008 CFG0_LOCK6_KICK0_PROXY
  [31:0] LOCK6_KICK0_PROXY — - KICK0 component
0x1B00C CFG0_LOCK6_KICK1_PROXY
  [31:0] LOCK6_KICK1_PROXY — - KICK1 component
{0x1B100+4i} CFG0_CLAIMREG_P6_R{i} (i=0..8)
  [31:0] CLAIMREG_P6_R{i} — Claim bits for Partition 6
